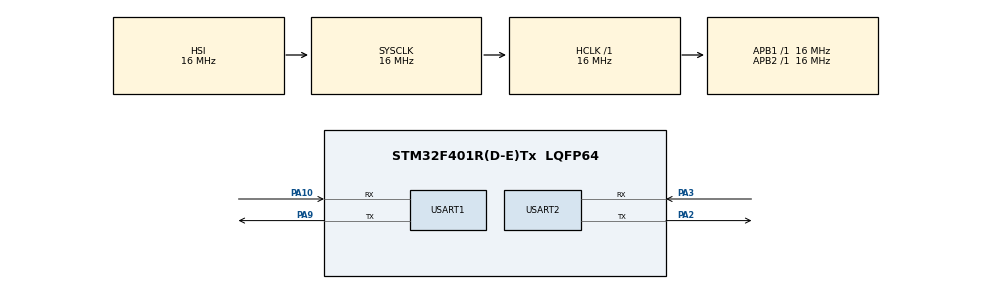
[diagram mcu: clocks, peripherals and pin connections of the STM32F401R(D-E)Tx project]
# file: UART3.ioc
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Mcu.Family=STM32F4
Mcu.Name=STM32F401R(D-E)Tx
Mcu.Package=LQFP64
NVIC.PriorityGroup=NVIC_PRIORITYGROUP_4
NVIC.USART1_IRQn=true\:0\:0\:false\:false\:true
NVIC.USART2_IRQn=true\:0\:0\:false\:false\:true
PA10.Mode=Asynchronous
PA10.Signal=USART1_RX
PA2.Mode=Asynchronous
PA2.Signal=USART2_TX
PA3.Mode=Asynchronous
PA3.Signal=USART2_RX
PA9.Mode=Asynchronous
PA9.Signal=USART1_TX
ProjectManager.HeapSize=0x200
ProjectManager.StackSize=0x400
ProjectManager.TargetToolchain=TrueSTUDIO
RCC.AHBFreq_Value=16000000
RCC.APB1Freq_Value=16000000
RCC.APB2Freq_Value=16000000
RCC.CortexFreq_Value=16000000
RCC.HSE_VALUE=25000000
RCC.HSI_VALUE=16000000
RCC.LSE_VALUE=32768
RCC.SYSCLKFreq_VALUE=16000000
RCC.VCOOutputFreq_Value=192000000
board=UART3

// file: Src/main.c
/**
  ******************************************************************************
  * File Name          : main.c
  * Description        : Main program body
  ******************************************************************************
  *
  * COPYRIGHT(c) 2016 STMicroelectronics
  *
  * Redistribution and use in source and binary forms, with or without modification,
  * are permitted provided that the following conditions are met:
  *   1. Redistributions of source code must retain the above copyright notice,
  *      this list of conditions and the following disclaimer.
  *   2. Redistributions in binary form must reproduce the above copyright notice,
  *      this list of conditions and the following disclaimer in the documentation
  *      and/or other materials provided with the distribution.
  *   3. Neither the name of STMicroelectronics nor the names of its contributors
  *      may be used to endorse or promote products derived from this software
  *      without specific prior written permission.
  *
  * THIS SOFTWARE IS PROVIDED BY THE COPYRIGHT HOLDERS AND CONTRIBUTORS "AS IS"
  * AND ANY EXPRESS OR IMPLIED WARRANTIES, INCLUDING, BUT NOT LIMITED TO, THE
  * IMPLIED WARRANTIES OF MERCHANTABILITY AND FITNESS FOR A PARTICULAR PURPOSE ARE
  * DISCLAIMED. IN NO EVENT SHALL THE COPYRIGHT HOLDER OR CONTRIBUTORS BE LIABLE
  * FOR ANY DIRECT, INDIRECT, INCIDENTAL, SPECIAL, EXEMPLARY, OR CONSEQUENTIAL
  * DAMAGES (INCLUDING, BUT NOT LIMITED TO, PROCUREMENT OF SUBSTITUTE GOODS OR
  * SERVICES; LOSS OF USE, DATA, OR PROFITS; OR BUSINESS INTERRUPTION) HOWEVER
  * CAUSED AND ON ANY THEORY OF LIABILITY, WHETHER IN CONTRACT, STRICT LIABILITY,
  * OR TORT (INCLUDING NEGLIGENCE OR OTHERWISE) ARISING IN ANY WAY OUT OF THE USE
  * OF THIS SOFTWARE, EVEN IF ADVISED OF THE POSSIBILITY OF SUCH DAMAGE.
  *
  ******************************************************************************
  */
#include "stm32f4xx_hal.h"

UART_HandleTypeDef huart1;
UART_HandleTypeDef huart2;

/* USER CODE BEGIN PV */
/* Private variables ---------------------------------------------------------*/
uint8_t buffer_tx[10]={10,11,12,13,14,15,16,17,18,19};
uint8_t buffer_rx[10];
/* USER CODE END PV */

void SystemClock_Config(void);
static void MX_GPIO_Init(void);
static void MX_USART1_UART_Init(void);
static void MX_USART2_UART_Init(void);

/* USER CODE BEGIN PFP */
/* Private function prototypes -----------------------------------------------*/

/* USER CODE END PFP */

/* USER CODE BEGIN 0 */
void HAL_UART_TxCpltCallback(UART_HandleTypeDef *huart){
}

void HAL_UART_RxCpltCallback(UART_HandleTypeDef *huart){
	if(huart->Instance==USART1){
		while(1);
	}
	if(huart->Instance==USART2){
		while(1);
	}
}
/* USER CODE END 0 */

int main(void)
{

  /* MCU Configuration----------------------------------------------------------*/

  /* Reset of all peripherals, Initializes the Flash interface and the Systick. */
  HAL_Init();

  /* Configure the system clock */
  SystemClock_Config();

  /* Initialize all configured peripherals */
  MX_GPIO_Init();
  MX_USART1_UART_Init();
  MX_USART2_UART_Init();

  /* USER CODE BEGIN 2 */
  HAL_UART_Receive_IT(&huart2,buffer_rx,10);
  HAL_UART_Transmit_IT(&huart1,buffer_tx,10);
  /* USER CODE END 2 */

  /* Infinite loop */
  while (1)
  {

  }

}

/** System Clock Configuration
*/
void SystemClock_Config(void)
{

  RCC_OscInitTypeDef RCC_OscInitStruct;
  RCC_ClkInitTypeDef RCC_ClkInitStruct;

  __HAL_RCC_PWR_CLK_ENABLE();

  __HAL_PWR_VOLTAGESCALING_CONFIG(PWR_REGULATOR_VOLTAGE_SCALE2);

  RCC_OscInitStruct.OscillatorType = RCC_OSCILLATORTYPE_HSI;
  RCC_OscInitStruct.HSIState = RCC_HSI_ON;
  RCC_OscInitStruct.HSICalibrationValue = 16;
  RCC_OscInitStruct.PLL.PLLState = RCC_PLL_NONE;
  HAL_RCC_OscConfig(&RCC_OscInitStruct);

  RCC_ClkInitStruct.ClockType = RCC_CLOCKTYPE_HCLK|RCC_CLOCKTYPE_SYSCLK
                              |RCC_CLOCKTYPE_PCLK1|RCC_CLOCKTYPE_PCLK2;
  RCC_ClkInitStruct.SYSCLKSource = RCC_SYSCLKSOURCE_HSI;
  RCC_ClkInitStruct.AHBCLKDivider = RCC_SYSCLK_DIV1;
  RCC_ClkInitStruct.APB1CLKDivider = RCC_HCLK_DIV1;
  RCC_ClkInitStruct.APB2CLKDivider = RCC_HCLK_DIV1;
  HAL_RCC_ClockConfig(&RCC_ClkInitStruct, FLASH_LATENCY_0);

  HAL_SYSTICK_Config(HAL_RCC_GetHCLKFreq()/1000);

  HAL_SYSTICK_CLKSourceConfig(SYSTICK_CLKSOURCE_HCLK);

  /* SysTick_IRQn interrupt configuration */
  HAL_NVIC_SetPriority(SysTick_IRQn, 0, 0);
}

/* USART1 init function */
void MX_USART1_UART_Init(void)
{

  huart1.Instance = USART1;
  huart1.Init.BaudRate = 115200;
  huart1.Init.WordLength = UART_WORDLENGTH_8B;
  huart1.Init.StopBits = UART_STOPBITS_1;
  huart1.Init.Parity = UART_PARITY_NONE;
  huart1.Init.Mode = UART_MODE_TX_RX;
  huart1.Init.HwFlowCtl = UART_HWCONTROL_NONE;
  huart1.Init.OverSampling = UART_OVERSAMPLING_16;
  HAL_UART_Init(&huart1);

}

/* USART2 init function */
void MX_USART2_UART_Init(void)
{

  huart2.Instance = USART2;
  huart2.Init.BaudRate = 115200;
  huart2.Init.WordLength = UART_WORDLENGTH_8B;
  huart2.Init.StopBits = UART_STOPBITS_1;
  huart2.Init.Parity = UART_PARITY_NONE;
  huart2.Init.Mode = UART_MODE_TX_RX;
  huart2.Init.HwFlowCtl = UART_HWCONTROL_NONE;
  huart2.Init.OverSampling = UART_OVERSAMPLING_16;
  HAL_UART_Init(&huart2);

}

/** Pinout Configuration
*/
void MX_GPIO_Init(void)
{

  /* GPIO Ports Clock Enable */
  __HAL_RCC_GPIOA_CLK_ENABLE();

}

/************************ (C) COPYRIGHT STMicroelectronics *****END OF FILE****/
